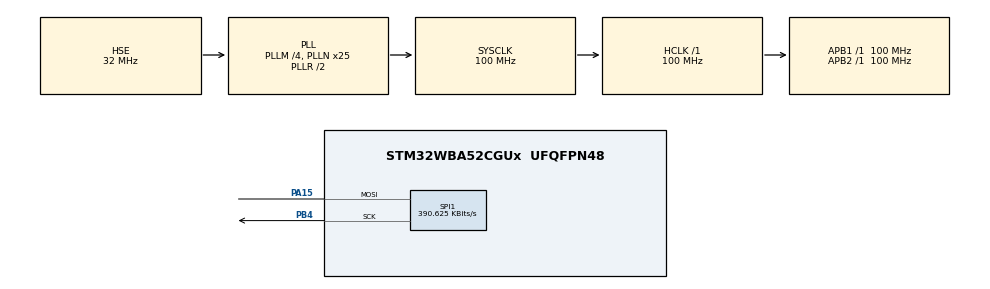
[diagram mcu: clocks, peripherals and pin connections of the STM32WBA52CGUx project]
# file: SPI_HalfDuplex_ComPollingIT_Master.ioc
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CORTEX_M33_NS.userName=CORTEX_M33
Mcu.Family=STM32WBA
Mcu.Name=STM32WBA52CGUx
Mcu.Package=UFQFPN48
NVIC.PriorityGroup=NVIC_PRIORITYGROUP_4
OSC_IN.Mode=HSE-External-Oscillator
OSC_IN.Signal=RCC_OSC_IN
OSC_OUT.Mode=HSE-External-Oscillator
OSC_OUT.Signal=RCC_OSC_OUT
PA15\ (JTDI).GPIO_PuPd=GPIO_PULLDOWN
PA15\ (JTDI).GPIO_Speed=GPIO_SPEED_FREQ_HIGH
PA15\ (JTDI).Mode=Simplex_Bidirectional_Master
PA15\ (JTDI).Signal=SPI1_MOSI
PB4\ (NJTRST).GPIO_PuPd=GPIO_PULLDOWN
PB4\ (NJTRST).GPIO_Speed=GPIO_SPEED_FREQ_HIGH
PB4\ (NJTRST).Mode=Simplex_Bidirectional_Master
PB4\ (NJTRST).Signal=SPI1_SCK
ProjectManager.HeapSize=0x200
ProjectManager.StackSize=0x400
ProjectManager.TargetToolchain=EWARM V9.20
RCC.ADCFreq_Value=100000000
RCC.AHB5CLKDivider=DIV4
RCC.AHBFreq_Value=100000000
RCC.APB1Freq_Value=100000000
RCC.APB1TimFreq_Value=100000000
RCC.APB2Freq_Value=100000000
RCC.APB2TimFreq_Value=100000000
RCC.CortexFreq_Value=100000000
RCC.HCLKFreq_Value=100000000
RCC.HSE_VALUE=32000000
RCC.HSI_VALUE=16000000
RCC.LSE_VALUE=32768
RCC.PLLFRACN=0
RCC.PLLM=4
RCC.PLLN=25
RCC.PLLSourceVirtual=RCC_PLLSOURCE_HSE
RCC.SYSCLKFreq_VALUE=100000000
RCC.SYSCLKSourceVirtual=RCC_SYSCLKSOURCE_PLLCLK
RCC.VCOOutputFreq_Value=200000000
SPI1.BaudRatePrescaler=SPI_BAUDRATEPRESCALER_256
SPI1.CLKPhase=SPI_PHASE_1EDGE
SPI1.CLKPolarity=SPI_POLARITY_LOW
SPI1.CalculateBaudRate=390.625 KBits/s
SPI1.DataSize=SPI_DATASIZE_8BIT
SPI1.Direction=SPI_DIRECTION_1LINE
SPI1.Mode=SPI_MODE_MASTER
SPI1.NSSPMode=SPI_NSS_PULSE_DISABLE
SPI1.VirtualType=VM_MASTER
VP_ICACHE_VS_ICACHE.Mode=DirectMappedCache
VP_PWR_VS_SECSignals.Mode=Security/Privilege
board=custom

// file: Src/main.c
/* USER CODE BEGIN Header */
/**
  ******************************************************************************
  * @file    SPI/SPI_HalfDuplex_ComPollingIT_Master/Src/main.c
  * @author  MCD Application Team
  * @brief   This sample code shows how to use STM32WBAxx SPI HAL API to transmit
  *          and receive a data buffer with a communication process based on
  *          Interrupt transfer.
  *          The communication is done using 2 Boards.
  ******************************************************************************
  * @attention
  *
  * Copyright (c) 2023 STMicroelectronics.
  * All rights reserved.
  *
  * This software is licensed under terms that can be found in the LICENSE file
  * in the root directory of this software component.
  * If no LICENSE file comes with this software, it is provided AS-IS.
  *
  ******************************************************************************
  */
/* USER CODE END Header */
#include "main.h"

/* USER CODE BEGIN PD */
enum {
	TRANSFER_WAIT,
	TRANSFER_COMPLETE,
	TRANSFER_ERROR
};
/* USER CODE END PD */

SPI_HandleTypeDef hspi1;

/* USER CODE BEGIN PV */
/* Buffer used for transmission */
uint8_t aTxBuffer[] = "**** SPI - Two Boards communication based on Polling (LL driver) for Master Board and Interrupt (HAL Driver) for Slave Board ****";
__IO uint8_t ubNbDataToTransmit  = BUFFERSIZE;
__IO uint8_t ubNbDataTransmitted = 0;

/* Buffer used for reception */
uint8_t aRxBuffer[BUFFERSIZE];

/* transfer state */
__IO uint32_t wTransferState = TRANSFER_WAIT;
/* USER CODE END PV */

void SystemClock_Config(void);
static void MX_GPIO_Init(void);
static void MX_ICACHE_Init(void);
static void MX_SPI1_Init(void);

int main(void)
{
  /* USER CODE BEGIN 1 */

  /* STM32WBAxx HAL library initialization:
       - Systick timer is configured by default as source of time base, but user
             can eventually implement his proper time base source (a general purpose
             timer for example or other time source), keeping in mind that Time base
             duration should be kept 1ms since PPP_TIMEOUT_VALUEs are defined and
             handled in milliseconds basis.
       - Set NVIC Group Priority to 4
       - Low Level Initialization
     */
  /* USER CODE END 1 */

  /* MCU Configuration--------------------------------------------------------*/

  /* Reset of all peripherals, Initializes the Flash interface and the Systick. */
  HAL_Init();

  /* Configure the system clock */
  SystemClock_Config();

  /* Initialize all configured peripherals */
  MX_GPIO_Init();
  MX_ICACHE_Init();
  MX_SPI1_Init();
  /* USER CODE BEGIN 2 */

  /* Configure LD2 and LD3 */
  BSP_LED_Init(LD2);
  BSP_LED_Init(LD3);

  /* Configure USER push-button */
  BSP_PB_Init(B1, BUTTON_MODE_GPIO);

  /* Wait for USER push-button press before starting the Communication */
  while (BSP_PB_GetState(B1) != GPIO_PIN_SET)
  {
    BSP_LED_Toggle(LD2);
    HAL_Delay(100);
  }
  BSP_LED_Off(LD2);

  /*##-1- Start the Half Duplex Communication process ########################*/
  /* Half Duplex Direction (Tx) not Done by HAL_Init. */
  LL_SPI_SetTransferDirection(hspi1.Instance, LL_SPI_HALF_DUPLEX_TX);

  /* Enable SPI before start transmission */
  LL_SPI_Enable(hspi1.Instance);

  LL_SPI_StartMasterTransfer(hspi1.Instance);

  while(ubNbDataToTransmit > 0)
  {
    /* Check TXP flag to transmit data */
    if(LL_SPI_IsActiveFlag_TXP(hspi1.Instance))
    {
      /* Transmit 8bit Data */
      LL_SPI_TransmitData8(hspi1.Instance, aTxBuffer[ubNbDataTransmitted++]);
      ubNbDataToTransmit--;
    }
    HAL_Delay(1);
  }

  /* Wait End Of Transmission: TXP set and Tx Fifo empty */

  while((LL_SPI_IsActiveFlag_TXP(hspi1.Instance) != 1));

  /* Disable SPI after End of Transmission */
  LL_SPI_Disable(hspi1.Instance);

  /* USER CODE END 2 */

  /* Infinite loop */
  while (1)
  {

  }
}

void SystemClock_Config(void)
{
  RCC_OscInitTypeDef RCC_OscInitStruct = {0};
  RCC_ClkInitTypeDef RCC_ClkInitStruct = {0};

  /** Configure the main internal regulator output voltage
  */
  if (HAL_PWREx_ControlVoltageScaling(PWR_REGULATOR_VOLTAGE_SCALE1) != HAL_OK)
  {
    Error_Handler();
  }

  /** Initializes the CPU, AHB and APB busses clocks
  */
  RCC_OscInitStruct.OscillatorType = RCC_OSCILLATORTYPE_HSE;
  RCC_OscInitStruct.HSEState = RCC_HSE_ON;
  RCC_OscInitStruct.HSEDiv = RCC_HSE_DIV1;
  RCC_OscInitStruct.PLL1.PLLState = RCC_PLL_ON;
  RCC_OscInitStruct.PLL1.PLLSource = RCC_PLLSOURCE_HSE;
  RCC_OscInitStruct.PLL1.PLLM = 4;
  RCC_OscInitStruct.PLL1.PLLN = 25;
  RCC_OscInitStruct.PLL1.PLLP = 2;
  RCC_OscInitStruct.PLL1.PLLQ = 2;
  RCC_OscInitStruct.PLL1.PLLR = 2;
  RCC_OscInitStruct.PLL1.PLLFractional = 0;
  if (HAL_RCC_OscConfig(&RCC_OscInitStruct) != HAL_OK)
  {
    Error_Handler();
  }

  /** Initializes the CPU, AHB and APB busses clocks
  */
  RCC_ClkInitStruct.ClockType = RCC_CLOCKTYPE_HCLK|RCC_CLOCKTYPE_SYSCLK
                              |RCC_CLOCKTYPE_PCLK1|RCC_CLOCKTYPE_PCLK2
                              |RCC_CLOCKTYPE_PCLK7|RCC_CLOCKTYPE_HCLK5;
  RCC_ClkInitStruct.SYSCLKSource = RCC_SYSCLKSOURCE_PLLCLK;
  RCC_ClkInitStruct.AHBCLKDivider = RCC_SYSCLK_DIV1;
  RCC_ClkInitStruct.APB1CLKDivider = RCC_HCLK_DIV1;
  RCC_ClkInitStruct.APB2CLKDivider = RCC_HCLK_DIV1;
  RCC_ClkInitStruct.APB7CLKDivider = RCC_HCLK_DIV1;
  RCC_ClkInitStruct.AHB5_PLL1_CLKDivider = RCC_SYSCLK_PLL1_DIV4;
  RCC_ClkInitStruct.AHB5_HSEHSI_CLKDivider = RCC_SYSCLK_HSEHSI_DIV1;

  if (HAL_RCC_ClockConfig(&RCC_ClkInitStruct, FLASH_LATENCY_3) != HAL_OK)
  {
    Error_Handler();
  }
}

static void MX_ICACHE_Init(void)
{

  /** Enable instruction cache in 1-way (direct mapped cache)
  */
  if (HAL_ICACHE_ConfigAssociativityMode(ICACHE_1WAY) != HAL_OK)
  {
    Error_Handler();
  }
  if (HAL_ICACHE_Enable() != HAL_OK)
  {
    Error_Handler();
  }

}

static void MX_SPI1_Init(void)
{

  SPI_AutonomousModeConfTypeDef HAL_SPI_AutonomousMode_Cfg_Struct = {0};

  /* SPI1 parameter configuration*/
  hspi1.Instance = SPI1;
  hspi1.Init.Mode = SPI_MODE_MASTER;
  hspi1.Init.Direction = SPI_DIRECTION_1LINE;
  hspi1.Init.DataSize = SPI_DATASIZE_8BIT;
  hspi1.Init.CLKPolarity = SPI_POLARITY_LOW;
  hspi1.Init.CLKPhase = SPI_PHASE_1EDGE;
  hspi1.Init.NSS = SPI_NSS_SOFT;
  hspi1.Init.BaudRatePrescaler = SPI_BAUDRATEPRESCALER_256;
  hspi1.Init.FirstBit = SPI_FIRSTBIT_MSB;
  hspi1.Init.TIMode = SPI_TIMODE_DISABLE;
  hspi1.Init.CRCCalculation = SPI_CRCCALCULATION_DISABLE;
  hspi1.Init.CRCPolynomial = 0x7;
  hspi1.Init.NSSPMode = SPI_NSS_PULSE_DISABLE;
  hspi1.Init.NSSPolarity = SPI_NSS_POLARITY_LOW;
  hspi1.Init.FifoThreshold = SPI_FIFO_THRESHOLD_01DATA;
  hspi1.Init.MasterSSIdleness = SPI_MASTER_SS_IDLENESS_00CYCLE;
  hspi1.Init.MasterInterDataIdleness = SPI_MASTER_INTERDATA_IDLENESS_00CYCLE;
  hspi1.Init.MasterReceiverAutoSusp = SPI_MASTER_RX_AUTOSUSP_DISABLE;
  hspi1.Init.MasterKeepIOState = SPI_MASTER_KEEP_IO_STATE_DISABLE;
  hspi1.Init.IOSwap = SPI_IO_SWAP_DISABLE;
  hspi1.Init.ReadyMasterManagement = SPI_RDY_MASTER_MANAGEMENT_INTERNALLY;
  hspi1.Init.ReadyPolarity = SPI_RDY_POLARITY_HIGH;
  if (HAL_SPI_Init(&hspi1) != HAL_OK)
  {
    Error_Handler();
  }
  HAL_SPI_AutonomousMode_Cfg_Struct.TriggerState = SPI_AUTO_MODE_DISABLE;
  if (HAL_SPIEx_SetConfigAutonomousMode(&hspi1, &HAL_SPI_AutonomousMode_Cfg_Struct) != HAL_OK)
  {
    Error_Handler();
  }

}

static void MX_GPIO_Init(void)
{

  /* GPIO Ports Clock Enable */
  __HAL_RCC_GPIOB_CLK_ENABLE();
  __HAL_RCC_GPIOA_CLK_ENABLE();

}

void Error_Handler(void)
{
  /* USER CODE BEGIN Error_Handler_Debug */
  /* Turn LD3 on */
  BSP_LED_On(LD3);
  while(1)
  {
  }
  /* USER CODE END Error_Handler_Debug */
}
